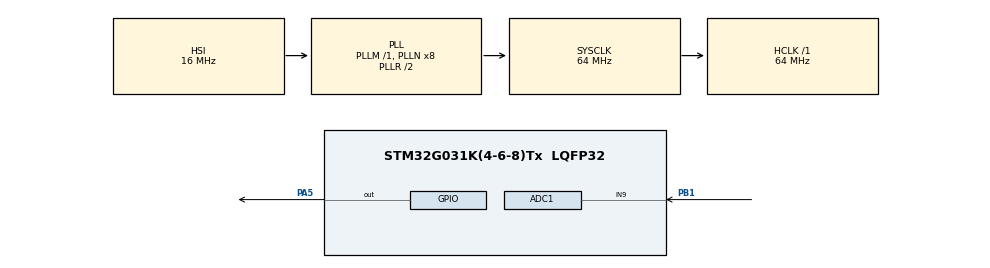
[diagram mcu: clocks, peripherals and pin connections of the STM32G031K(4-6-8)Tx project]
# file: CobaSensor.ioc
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ADC1.Channel-1\#ChannelRegularConversion=ADC_CHANNEL_9
ADC1.ContinuousConvMode=ENABLE
ADC1.NbrOfConversionFlag=1
ADC1.Rank-1\#ChannelRegularConversion=1
ADC1.SamplingTime-1\#ChannelRegularConversion=ADC_SAMPLINGTIME_COMMON_1
ADC1.SelectedChannel=ADC_CHANNEL_9
ADC1.master=1
Mcu.Family=STM32G0
Mcu.Name=STM32G031K(4-6-8)Tx
Mcu.Package=LQFP32
PA13.Mode=Serial_Wire
PA13.Signal=SYS_SWDIO
PA14-BOOT0.Mode=Serial_Wire
PA14-BOOT0.Signal=SYS_SWCLK
PA5.Signal=GPIO_Output
PB1.Mode=IN9
PB1.Signal=ADC1_IN9
ProjectManager.HeapSize=0x200
ProjectManager.StackSize=0x400
ProjectManager.TargetToolchain=STM32CubeIDE
RCC.ADCFreq_Value=64000000
RCC.AHBFreq_Value=64000000
RCC.CortexFreq_Value=64000000
RCC.EXTERNAL_CLOCK_VALUE=12288000
RCC.HCLKFreq_Value=64000000
RCC.HSE_VALUE=8000000
RCC.HSI_VALUE=16000000
RCC.SYSCLKFreq_VALUE=64000000
RCC.SYSCLKSource=RCC_SYSCLKSOURCE_PLLCLK
RCC.VCOOutputFreq_Value=128000000
TIM1.AutoReloadPreload=TIM_AUTORELOAD_PRELOAD_ENABLE
TIM1.Period=100-1
TIM1.Prescaler=12.8-1
VP_TIM1_VS_ClockSourceINT.Mode=Internal
board=custom

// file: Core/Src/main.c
/* USER CODE BEGIN Header */
/**
  ******************************************************************************
  * @file           : main.c
  * @brief          : Main program body
  ******************************************************************************
  * @attention
  *
  * Copyright (c) 2022 STMicroelectronics.
  * All rights reserved.
  *
  * This software is licensed under terms that can be found in the LICENSE file
  * in the root directory of this software component.
  * If no LICENSE file comes with this software, it is provided AS-IS.
  *
  ******************************************************************************
  */
/* USER CODE END Header */
#include "main.h"

ADC_HandleTypeDef hadc1;

TIM_HandleTypeDef htim1;

/* USER CODE BEGIN PV */
uint16_t readValue;
float Tegangan;
float Hambatan;
float TempC = 24;
float open_resistance = 35000;
float short_resistance = 200;
float short_CB = 240;
float open_CB = 255;
float CB = 0;
//float CB;
/* USER CODE END PV */

void SystemClock_Config(void);
static void MX_GPIO_Init(void);
static void MX_ADC1_Init(void);
static void MX_TIM1_Init(void);

int main(void)
{

  /* MCU Configuration--------------------------------------------------------*/

  /* Reset of all peripherals, Initializes the Flash interface and the Systick. */
  HAL_Init();

  /* Configure the system clock */
  SystemClock_Config();

  /* Initialize all configured peripherals */
  MX_GPIO_Init();
  MX_ADC1_Init();
  MX_TIM1_Init();
  /* USER CODE BEGIN 2 */
  HAL_ADC_Start(&hadc1);
//  HAL_TIM_PWM_Start(&htim1, TIM_CHANNEL_1);
  /* USER CODE END 2 */

  /* Infinite loop */
  /* USER CODE BEGIN WHILE */
  while (1)
  {
	  HAL_GPIO_WritePin(GPIOA, GPIO_PIN_5, 1);
	      HAL_Delay(20);
	      HAL_ADC_PollForConversion(&hadc1,1000);
	      readValue = HAL_ADC_GetValue(&hadc1);
	      Tegangan = readValue * 3.3 / 4095;

	      Hambatan = (5700 * (3.3 - Tegangan) / Tegangan);
	      HAL_GPIO_WritePin(GPIOA, GPIO_PIN_5, 0);
	      if (Hambatan > 550)
	      {
	    	  if (Hambatan > 8000)
	    	  {
	    		  CB = (-2.246) - 5.239*(Hambatan/1000.00)*(1 + 0.018*(TempC-24.00))- 0.06756*(Hambatan/1000.00)*(Hambatan/1000.00)*((1.00+0.018*(TempC-24.00))*(1.00+0.018*(TempC-24.00)));
	    	  }
	    	  else if (Hambatan>1000.00)
	    	  {

	    		  CB = -(-3.213 * (Hambatan/1000.00)-4.093)/(1-0.009733*(Hambatan/1000.00)-0.01205*(TempC)) ;

	    	  }
	    	  else
	    	  {

	    		  CB = ((Hambatan/1000.00)*23.156-12.736)*(1.00 + 0.018*(TempC-24.00));
	    	  }
	      }
	      else
	      {

	      	  if(Hambatan>300.00)
	      	  {
	      		  CB = 0.00;
	      	  }

	      	  if(Hambatan < 300.00 && Hambatan>=short_resistance)
	      	  {

	      		  CB = short_CB; //240 is a fault code for sensor terminal short
	      	  }
	      }

	      if(Hambatan>=open_resistance)
	      {

	      	  CB = open_CB; //255 is a fault code for open circuit or sensor not present
	      }
	      HAL_Delay(500);
    /* USER CODE END WHILE */

  }
}

void SystemClock_Config(void)
{
  RCC_OscInitTypeDef RCC_OscInitStruct = {0};
  RCC_ClkInitTypeDef RCC_ClkInitStruct = {0};

  /** Configure the main internal regulator output voltage
  */
  HAL_PWREx_ControlVoltageScaling(PWR_REGULATOR_VOLTAGE_SCALE1);
  /** Initializes the RCC Oscillators according to the specified parameters
  * in the RCC_OscInitTypeDef structure.
  */
  RCC_OscInitStruct.OscillatorType = RCC_OSCILLATORTYPE_HSI;
  RCC_OscInitStruct.HSIState = RCC_HSI_ON;
  RCC_OscInitStruct.HSIDiv = RCC_HSI_DIV1;
  RCC_OscInitStruct.HSICalibrationValue = RCC_HSICALIBRATION_DEFAULT;
  RCC_OscInitStruct.PLL.PLLState = RCC_PLL_ON;
  RCC_OscInitStruct.PLL.PLLSource = RCC_PLLSOURCE_HSI;
  RCC_OscInitStruct.PLL.PLLM = RCC_PLLM_DIV1;
  RCC_OscInitStruct.PLL.PLLN = 8;
  RCC_OscInitStruct.PLL.PLLP = RCC_PLLP_DIV2;
  RCC_OscInitStruct.PLL.PLLQ = RCC_PLLQ_DIV2;
  RCC_OscInitStruct.PLL.PLLR = RCC_PLLR_DIV2;
  if (HAL_RCC_OscConfig(&RCC_OscInitStruct) != HAL_OK)
  {
    Error_Handler();
  }
  /** Initializes the CPU, AHB and APB buses clocks
  */
  RCC_ClkInitStruct.ClockType = RCC_CLOCKTYPE_HCLK|RCC_CLOCKTYPE_SYSCLK
                              |RCC_CLOCKTYPE_PCLK1;
  RCC_ClkInitStruct.SYSCLKSource = RCC_SYSCLKSOURCE_PLLCLK;
  RCC_ClkInitStruct.AHBCLKDivider = RCC_SYSCLK_DIV1;
  RCC_ClkInitStruct.APB1CLKDivider = RCC_HCLK_DIV1;

  if (HAL_RCC_ClockConfig(&RCC_ClkInitStruct, FLASH_LATENCY_2) != HAL_OK)
  {
    Error_Handler();
  }
}

static void MX_ADC1_Init(void)
{

  ADC_ChannelConfTypeDef sConfig = {0};

  /** Configure the global features of the ADC (Clock, Resolution, Data Alignment and number of conversion)
  */
  hadc1.Instance = ADC1;
  hadc1.Init.ClockPrescaler = ADC_CLOCK_SYNC_PCLK_DIV2;
  hadc1.Init.Resolution = ADC_RESOLUTION_12B;
  hadc1.Init.DataAlign = ADC_DATAALIGN_RIGHT;
  hadc1.Init.ScanConvMode = ADC_SCAN_DISABLE;
  hadc1.Init.EOCSelection = ADC_EOC_SINGLE_CONV;
  hadc1.Init.LowPowerAutoWait = DISABLE;
  hadc1.Init.LowPowerAutoPowerOff = DISABLE;
  hadc1.Init.ContinuousConvMode = ENABLE;
  hadc1.Init.NbrOfConversion = 1;
  hadc1.Init.DiscontinuousConvMode = DISABLE;
  hadc1.Init.ExternalTrigConv = ADC_SOFTWARE_START;
  hadc1.Init.ExternalTrigConvEdge = ADC_EXTERNALTRIGCONVEDGE_NONE;
  hadc1.Init.DMAContinuousRequests = DISABLE;
  hadc1.Init.Overrun = ADC_OVR_DATA_PRESERVED;
  hadc1.Init.SamplingTimeCommon1 = ADC_SAMPLETIME_1CYCLE_5;
  hadc1.Init.SamplingTimeCommon2 = ADC_SAMPLETIME_1CYCLE_5;
  hadc1.Init.OversamplingMode = DISABLE;
  hadc1.Init.TriggerFrequencyMode = ADC_TRIGGER_FREQ_HIGH;
  if (HAL_ADC_Init(&hadc1) != HAL_OK)
  {
    Error_Handler();
  }
  /** Configure Regular Channel
  */
  sConfig.Channel = ADC_CHANNEL_9;
  sConfig.Rank = ADC_REGULAR_RANK_1;
  sConfig.SamplingTime = ADC_SAMPLINGTIME_COMMON_1;
  if (HAL_ADC_ConfigChannel(&hadc1, &sConfig) != HAL_OK)
  {
    Error_Handler();
  }

}

static void MX_TIM1_Init(void)
{

  TIM_ClockConfigTypeDef sClockSourceConfig = {0};
  TIM_MasterConfigTypeDef sMasterConfig = {0};

  htim1.Instance = TIM1;
  htim1.Init.Prescaler = 12.8-1;
  htim1.Init.CounterMode = TIM_COUNTERMODE_UP;
  htim1.Init.Period = 100-1;
  htim1.Init.ClockDivision = TIM_CLOCKDIVISION_DIV1;
  htim1.Init.RepetitionCounter = 0;
  htim1.Init.AutoReloadPreload = TIM_AUTORELOAD_PRELOAD_ENABLE;
  if (HAL_TIM_Base_Init(&htim1) != HAL_OK)
  {
    Error_Handler();
  }
  sClockSourceConfig.ClockSource = TIM_CLOCKSOURCE_INTERNAL;
  if (HAL_TIM_ConfigClockSource(&htim1, &sClockSourceConfig) != HAL_OK)
  {
    Error_Handler();
  }
  sMasterConfig.MasterOutputTrigger = TIM_TRGO_RESET;
  sMasterConfig.MasterOutputTrigger2 = TIM_TRGO2_RESET;
  sMasterConfig.MasterSlaveMode = TIM_MASTERSLAVEMODE_DISABLE;
  if (HAL_TIMEx_MasterConfigSynchronization(&htim1, &sMasterConfig) != HAL_OK)
  {
    Error_Handler();
  }

}

static void MX_GPIO_Init(void)
{
  GPIO_InitTypeDef GPIO_InitStruct = {0};

  /* GPIO Ports Clock Enable */
  __HAL_RCC_GPIOA_CLK_ENABLE();
  __HAL_RCC_GPIOB_CLK_ENABLE();

  /*Configure GPIO pin Output Level */
  HAL_GPIO_WritePin(GPIOA, GPIO_PIN_5, GPIO_PIN_RESET);

  /*Configure GPIO pin : PA5 */
  GPIO_InitStruct.Pin = GPIO_PIN_5;
  GPIO_InitStruct.Mode = GPIO_MODE_OUTPUT_PP;
  GPIO_InitStruct.Pull = GPIO_NOPULL;
  GPIO_InitStruct.Speed = GPIO_SPEED_FREQ_LOW;
  HAL_GPIO_Init(GPIOA, &GPIO_InitStruct);

}

void Error_Handler(void)
{
  __disable_irq();
  while (1)
  {
  }
}
